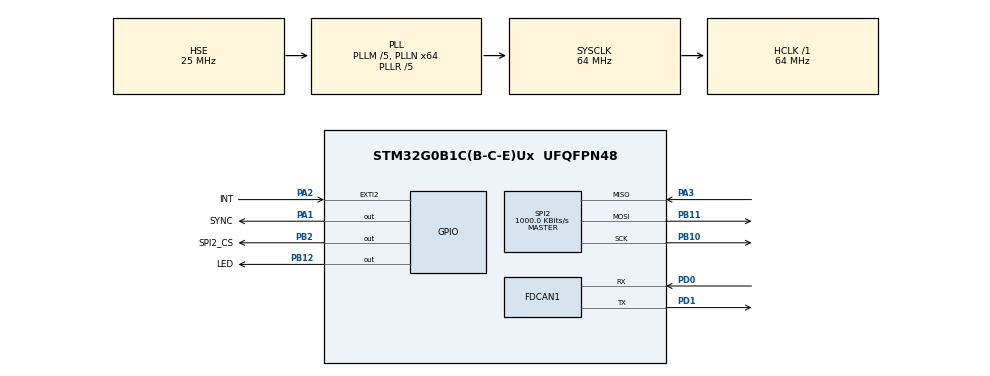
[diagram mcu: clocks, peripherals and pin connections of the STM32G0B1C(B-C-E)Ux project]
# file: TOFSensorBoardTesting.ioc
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FDCAN1.CalculateBaudRateNominal=500000
FDCAN1.CalculateTimeBitNominal=2000
FDCAN1.CalculateTimeQuantumNominal=125.0
FDCAN1.DataPrescaler=2
FDCAN1.DataTimeSeg1=11
FDCAN1.DataTimeSeg2=4
FDCAN1.FrameFormat=FDCAN_FRAME_FD_BRS
FDCAN1.NominalPrescaler=8
FDCAN1.NominalTimeSeg1=13
FDCAN1.NominalTimeSeg2=2
Mcu.Family=STM32G0
Mcu.Name=STM32G0B1C(B-C-E)Ux
Mcu.Package=UFQFPN48
NVIC.TIM16_FDCAN_IT0_IRQn=true\:0\:0\:false\:false\:true\:true\:true\:true
PA1.GPIO_Label=SYNC
PA1.Signal=GPIO_Output
PA13.Mode=Serial_Wire
PA13.Signal=SYS_SWDIO
PA14-BOOT0.Mode=Serial_Wire
PA14-BOOT0.Signal=SYS_SWCLK
PA2.GPIO_Label=INT
PA2.Signal=GPXTI2
PA3.Mode=Full_Duplex_Master
PA3.Signal=SPI2_MISO
PB10.Mode=Full_Duplex_Master
PB10.Signal=SPI2_SCK
PB11.Mode=Full_Duplex_Master
PB11.Signal=SPI2_MOSI
PB12.GPIO_Label=LED
PB12.Signal=GPIO_Output
PB2.GPIO_Label=SPI2_CS
PB2.Signal=GPIO_Output
PD0.Mode=FDCAN_Activate
PD0.Signal=FDCAN1_RX
PD1.Mode=FDCAN_Activate
PD1.Signal=FDCAN1_TX
PF0-OSC_IN\ (PF0).Mode=HSE-External-Oscillator
PF0-OSC_IN\ (PF0).Signal=RCC_OSC_IN
PF1-OSC_OUT\ (PF1).Mode=HSE-External-Oscillator
PF1-OSC_OUT\ (PF1).Signal=RCC_OSC_OUT
ProjectManager.HeapSize=0x200
ProjectManager.StackSize=0x400
ProjectManager.TargetToolchain=CMake
RCC.ADCFreq_Value=64000000
RCC.AHBFreq_Value=64000000
RCC.CortexFreq_Value=64000000
RCC.EXTERNAL_CLOCK_VALUE=48000
RCC.HCLKFreq_Value=64000000
RCC.HSE_VALUE=25000000
RCC.HSI48_VALUE=48000000
RCC.HSI_VALUE=16000000
RCC.LSE_VALUE=32768
RCC.PLLM=RCC_PLLM_DIV5
RCC.PLLN=64
RCC.PLLR=RCC_PLLR_DIV5
RCC.PLLSourceVirtual=RCC_PLLSOURCE_HSE
RCC.SYSCLKFreq_VALUE=64000000
RCC.SYSCLKSource=RCC_SYSCLKSOURCE_PLLCLK
RCC.USBFreq_Value=48000000
RCC.VCOOutputFreq_Value=320000000
SPI2.BaudRatePrescaler=SPI_BAUDRATEPRESCALER_64
SPI2.CLKPhase=SPI_PHASE_2EDGE
SPI2.CLKPolarity=SPI_POLARITY_HIGH
SPI2.CRCCalculation=SPI_CRCCALCULATION_DISABLE
SPI2.CalculateBaudRate=1000.0 KBits/s
SPI2.DataSize=SPI_DATASIZE_8BIT
SPI2.Direction=SPI_DIRECTION_2LINES
SPI2.Mode=SPI_MODE_MASTER
SPI2.VirtualType=VM_MASTER
VP_SYS_VS_DBSignals.Mode=DisableDeadBatterySignals
board=custom

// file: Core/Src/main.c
/* USER CODE BEGIN Header */
/**
  ******************************************************************************
  * @file           : main.c
  * @brief          : Main program body
  ******************************************************************************
  * @attention
  *
  * Copyright (c) 2026 STMicroelectronics.
  * All rights reserved.
  *
  * This software is licensed under terms that can be found in the LICENSE file
  * in the root directory of this software component.
  * If no LICENSE file comes with this software, it is provided AS-IS.
  *
  ******************************************************************************
  */
/* USER CODE END Header */
#include "main.h"

/* USER CODE BEGIN Includes */
#include "vl53l8cx_api.h"
/* USER CODE END Includes */

FDCAN_HandleTypeDef hfdcan1;

SPI_HandleTypeDef hspi2;

void SystemClock_Config(void);
static void MX_GPIO_Init(void);
static void MX_FDCAN1_Init(void);
static void MX_SPI2_Init(void);

int main(void)
{

  /* MCU Configuration--------------------------------------------------------*/

  /* Reset of all peripherals, Initializes the Flash interface and the Systick. */
  HAL_Init();

  /* Configure the system clock */
  SystemClock_Config();

  /* Initialize all configured peripherals */
  MX_GPIO_Init();
  MX_FDCAN1_Init();
  MX_SPI2_Init();

  /* Infinite loop */
  while (1)
  {

  }
}

void SystemClock_Config(void)
{
  RCC_OscInitTypeDef RCC_OscInitStruct = {0};
  RCC_ClkInitTypeDef RCC_ClkInitStruct = {0};

  /** Configure the main internal regulator output voltage
  */
  HAL_PWREx_ControlVoltageScaling(PWR_REGULATOR_VOLTAGE_SCALE1);

  /** Initializes the RCC Oscillators according to the specified parameters
  * in the RCC_OscInitTypeDef structure.
  */
  RCC_OscInitStruct.OscillatorType = RCC_OSCILLATORTYPE_HSE;
  RCC_OscInitStruct.HSEState = RCC_HSE_ON;
  RCC_OscInitStruct.PLL.PLLState = RCC_PLL_ON;
  RCC_OscInitStruct.PLL.PLLSource = RCC_PLLSOURCE_HSE;
  RCC_OscInitStruct.PLL.PLLM = RCC_PLLM_DIV5;
  RCC_OscInitStruct.PLL.PLLN = 64;
  RCC_OscInitStruct.PLL.PLLP = RCC_PLLP_DIV2;
  RCC_OscInitStruct.PLL.PLLQ = RCC_PLLQ_DIV2;
  RCC_OscInitStruct.PLL.PLLR = RCC_PLLR_DIV5;
  if (HAL_RCC_OscConfig(&RCC_OscInitStruct) != HAL_OK)
  {
    Error_Handler();
  }

  /** Initializes the CPU, AHB and APB buses clocks
  */
  RCC_ClkInitStruct.ClockType = RCC_CLOCKTYPE_HCLK|RCC_CLOCKTYPE_SYSCLK
                              |RCC_CLOCKTYPE_PCLK1;
  RCC_ClkInitStruct.SYSCLKSource = RCC_SYSCLKSOURCE_PLLCLK;
  RCC_ClkInitStruct.AHBCLKDivider = RCC_SYSCLK_DIV1;
  RCC_ClkInitStruct.APB1CLKDivider = RCC_HCLK_DIV1;

  if (HAL_RCC_ClockConfig(&RCC_ClkInitStruct, FLASH_LATENCY_2) != HAL_OK)
  {
    Error_Handler();
  }
}

static void MX_FDCAN1_Init(void)
{

  hfdcan1.Instance = FDCAN1;
  hfdcan1.Init.ClockDivider = FDCAN_CLOCK_DIV1;
  hfdcan1.Init.FrameFormat = FDCAN_FRAME_FD_BRS;
  hfdcan1.Init.Mode = FDCAN_MODE_NORMAL;
  hfdcan1.Init.AutoRetransmission = DISABLE;
  hfdcan1.Init.TransmitPause = DISABLE;
  hfdcan1.Init.ProtocolException = DISABLE;
  hfdcan1.Init.NominalPrescaler = 8;
  hfdcan1.Init.NominalSyncJumpWidth = 1;
  hfdcan1.Init.NominalTimeSeg1 = 13;
  hfdcan1.Init.NominalTimeSeg2 = 2;
  hfdcan1.Init.DataPrescaler = 2;
  hfdcan1.Init.DataSyncJumpWidth = 1;
  hfdcan1.Init.DataTimeSeg1 = 11;
  hfdcan1.Init.DataTimeSeg2 = 4;
  hfdcan1.Init.StdFiltersNbr = 0;
  hfdcan1.Init.ExtFiltersNbr = 0;
  hfdcan1.Init.TxFifoQueueMode = FDCAN_TX_FIFO_OPERATION;
  if (HAL_FDCAN_Init(&hfdcan1) != HAL_OK)
  {
    Error_Handler();
  }

}

static void MX_SPI2_Init(void)
{

  /* SPI2 parameter configuration*/
  hspi2.Instance = SPI2;
  hspi2.Init.Mode = SPI_MODE_MASTER;
  hspi2.Init.Direction = SPI_DIRECTION_2LINES;
  hspi2.Init.DataSize = SPI_DATASIZE_8BIT;
  hspi2.Init.CLKPolarity = SPI_POLARITY_HIGH;
  hspi2.Init.CLKPhase = SPI_PHASE_2EDGE;
  hspi2.Init.NSS = SPI_NSS_SOFT;
  hspi2.Init.BaudRatePrescaler = SPI_BAUDRATEPRESCALER_64;
  hspi2.Init.FirstBit = SPI_FIRSTBIT_MSB;
  hspi2.Init.TIMode = SPI_TIMODE_DISABLE;
  hspi2.Init.CRCCalculation = SPI_CRCCALCULATION_DISABLE;
  hspi2.Init.CRCPolynomial = 7;
  hspi2.Init.CRCLength = SPI_CRC_LENGTH_DATASIZE;
  hspi2.Init.NSSPMode = SPI_NSS_PULSE_DISABLE;
  if (HAL_SPI_Init(&hspi2) != HAL_OK)
  {
    Error_Handler();
  }

}

static void MX_GPIO_Init(void)
{
  GPIO_InitTypeDef GPIO_InitStruct = {0};

  /* GPIO Ports Clock Enable */
  __HAL_RCC_GPIOF_CLK_ENABLE();
  __HAL_RCC_GPIOA_CLK_ENABLE();
  __HAL_RCC_GPIOB_CLK_ENABLE();
  __HAL_RCC_GPIOD_CLK_ENABLE();

  /*Configure GPIO pin Output Level */
  HAL_GPIO_WritePin(SYNC_GPIO_Port, SYNC_Pin, GPIO_PIN_RESET);

  /*Configure GPIO pin Output Level */
  HAL_GPIO_WritePin(GPIOB, SPI2_CS_Pin|LED_Pin, GPIO_PIN_RESET);

  /*Configure GPIO pin : SYNC_Pin */
  GPIO_InitStruct.Pin = SYNC_Pin;
  GPIO_InitStruct.Mode = GPIO_MODE_OUTPUT_PP;
  GPIO_InitStruct.Pull = GPIO_NOPULL;
  GPIO_InitStruct.Speed = GPIO_SPEED_FREQ_LOW;
  HAL_GPIO_Init(SYNC_GPIO_Port, &GPIO_InitStruct);

  /*Configure GPIO pin : INT_Pin */
  GPIO_InitStruct.Pin = INT_Pin;
  GPIO_InitStruct.Mode = GPIO_MODE_IT_RISING;
  GPIO_InitStruct.Pull = GPIO_NOPULL;
  HAL_GPIO_Init(INT_GPIO_Port, &GPIO_InitStruct);

  /*Configure GPIO pins : SPI2_CS_Pin LED_Pin */
  GPIO_InitStruct.Pin = SPI2_CS_Pin|LED_Pin;
  GPIO_InitStruct.Mode = GPIO_MODE_OUTPUT_PP;
  GPIO_InitStruct.Pull = GPIO_NOPULL;
  GPIO_InitStruct.Speed = GPIO_SPEED_FREQ_LOW;
  HAL_GPIO_Init(GPIOB, &GPIO_InitStruct);

}

void Error_Handler(void)
{
  __disable_irq();
  while (1)
  {
  }
}
